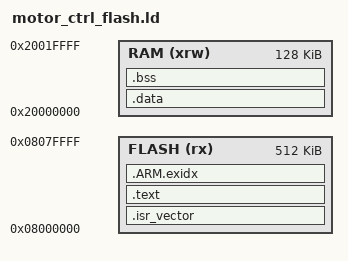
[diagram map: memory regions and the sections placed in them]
ENTRY(Reset_Handler)

MEMORY
{
  FLASH (rx)  : ORIGIN = 0x08000000, LENGTH = 512K
  RAM   (xrw) : ORIGIN = 0x20000000, LENGTH = 128K
}

_estack = ORIGIN(RAM) + LENGTH(RAM);

SECTIONS
{
  .isr_vector :
  {
    KEEP(*(.isr_vector))
  } > FLASH

  .text :
  {
    *(.text*)
    *(.rodata*)
    KEEP(*(.init))
    KEEP(*(.fini))
    . = ALIGN(4);
    _etext = .;
  } > FLASH

  .ARM.exidx :
  {
    *(.ARM.exidx*)
  } > FLASH

  _sidata = LOADADDR(.data);

  .data : AT(_etext)
  {
    . = ALIGN(4);
    _sdata = .;
    *(.data*)
    . = ALIGN(4);
    _edata = .;
  } > RAM

  .bss :
  {
    . = ALIGN(4);
    _sbss = .;
    *(.bss*)
    *(COMMON)
    . = ALIGN(4);
    _ebss = .;
  } > RAM

  . = ALIGN(4);
  end = .;

  /DISCARD/ :
  {
    *(.note.GNU-stack)
    *(.comment)
  }
}
